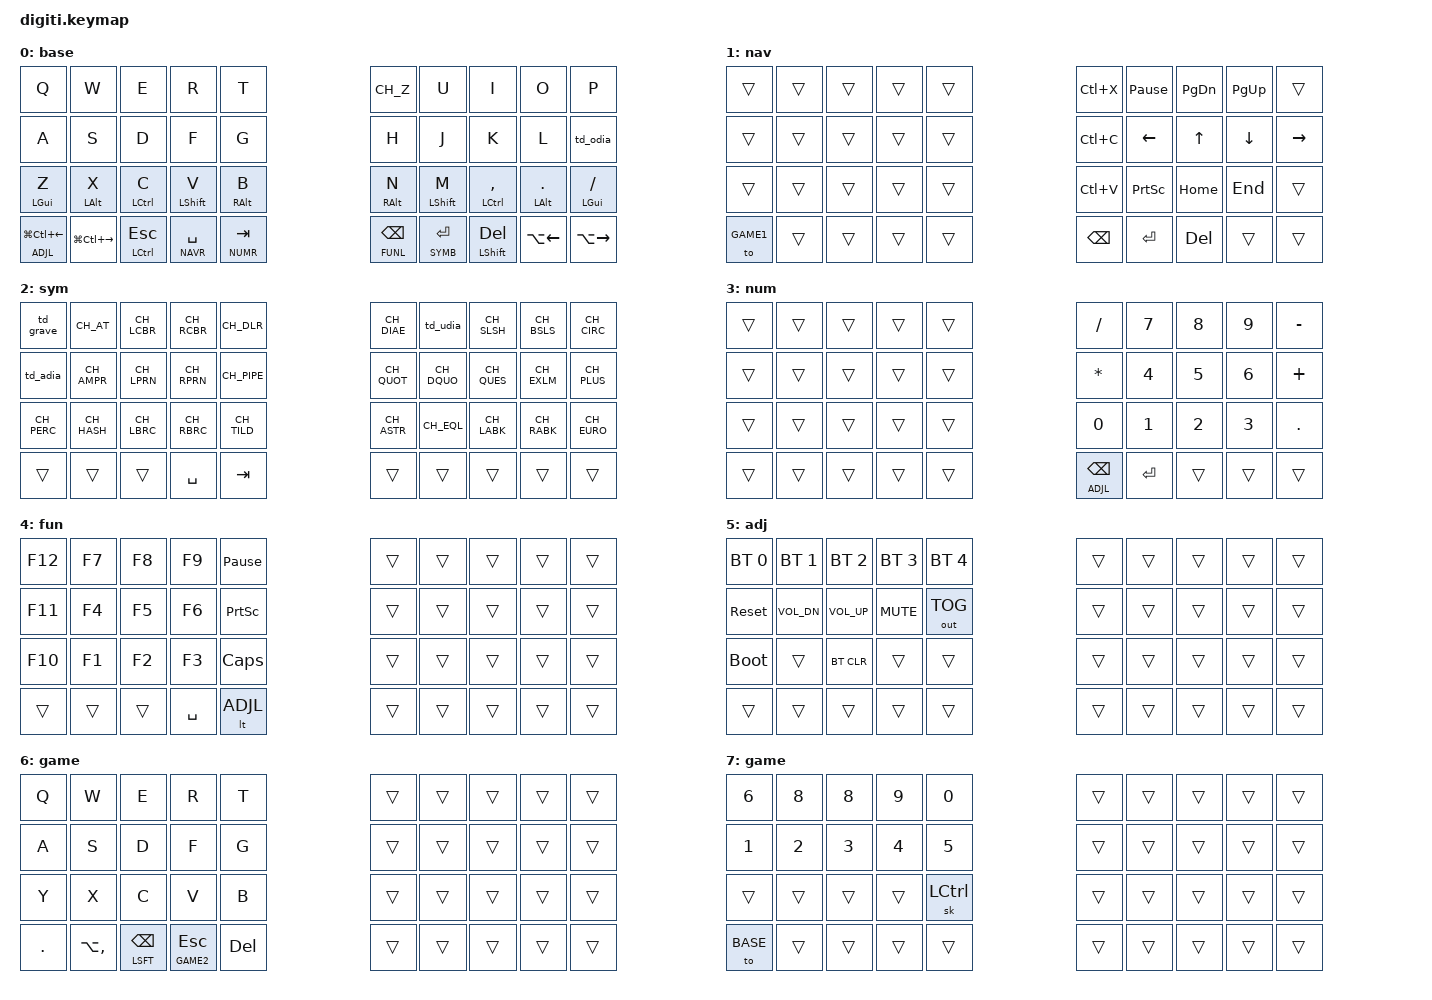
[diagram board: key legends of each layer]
/*
 * Copyright (c) 2021 The ZMK Contributors
 *
 * SPDX-License-Identifier: MIT
 */

 #include <behaviors.dtsi>
 #include <dt-bindings/zmk/keys.h>
 #include <dt-bindings/zmk/bt.h>
 #include <dt-bindings/zmk/ext_power.h>
 #include <dt-bindings/zmk/outputs.h>
 
 #include "swiss-keymap.h"
 
 #define BASE   0
 #define NAVR   1
 #define SYMB   2
 #define NUMR   3
 #define FUNL   4
 #define ADJL   5   
 #define GAME1  6    
 #define GAME2  7    
 
 / {
     macros {
        md_code_i: md_code_i {
            label = "MD Code Inline";
            compatible = "zmk,behavior-macro";
            #binding-cells = <0>;
            bindings
                = <&macro_tap_time 50>
                , <&macro_tap &kp CH_GRV>
                , <&macro_tap_time 10>
                , <&macro_tap &kp CH_GRV &kp LEFT>
                ;
        };
        md_code_b: md_code_b {
            label = "MD Code Block";
            compatible = "zmk,behavior-macro";
            #binding-cells = <0>;
            bindings
                = <&macro_tap_time 10>
                , <&macro_tap &kp CH_GRV &kp CH_GRV &kp CH_GRV &kp CH_GRV &kp CH_GRV &kp CH_GRV &kp LEFT &kp LEFT &kp LEFT &kp RET &kp RET &kp UP>
                ;
        };
        up_ch_adia: up_ch_adia {
            label = "Uppercase CH_ADIA";
            compatible = "zmk,behavior-macro";
            #binding-cells = <0>;
            bindings
                = <&macro_tap_time 10>
                , <&macro_tap &kp CLCK &kp CH_ADIA &kp CLCK>
                ;
        };
        up_ch_udia: up_ch_udia {
            label = "Uppercase CH_UDIA";
            compatible = "zmk,behavior-macro";
            #binding-cells = <0>;
            bindings
                = <&macro_tap_time 10>
                , <&macro_tap &kp CLCK &kp CH_UDIA &kp CLCK>
                ;
        };
        
        up_ch_odia: up_ch_odia {
            label = "Uppercase CH_ODIA";
            compatible = "zmk,behavior-macro";
            #binding-cells = <0>;
            bindings
                = <&macro_tap_time 10>
                , <&macro_tap &kp CLCK &kp CH_ODIA &kp CLCK>
                ;
        };
    };
     behaviors {
         hm: homerow_mods {
             compatible = "zmk,behavior-hold-tap";
             label = "HOMEROW_MODS";
             #binding-cells = <2>;
             tapping-term-ms = <180>;
             quick_tap_ms = <0>;
             flavor = "tap-preferred";
             bindings = <&kp>, <&kp>;
         };
         td_udia: tap_dance_udia {
            compatible = "zmk,behavior-tap-dance";
            label = "TAP_DANCE_UDIA";
            #binding-cells = <0>;
            tapping-term-ms = <200>;
            bindings = <&kp CH_UDIA>, <&up_ch_udia>;
        };
         td_adia: tap_dance_adia {
            compatible = "zmk,behavior-tap-dance";
            label = "TAP_DANCE_ADIA";
            #binding-cells = <0>;
            tapping-term-ms = <200>;
            bindings = <&kp CH_ADIA>, <&up_ch_adia>;
        };
         td_odia: tap_dance_odia {
            compatible = "zmk,behavior-tap-dance";
            label = "TAP_DANCE_ODIA";
            #binding-cells = <0>;
            tapping-term-ms = <200>;
            bindings = <&kp CH_ODIA>, <&up_ch_odia>;
        };
        td_grave: tap_dance_grave {
            compatible = "zmk,behavior-tap-dance";
            label = "TAP_DANCE_GRAVE";
            #binding-cells = <0>;
            tapping-term-ms = <300>;
            bindings = <&kp CH_GRV>, <&md_code_i>, <&md_code_b>;
        };
     };
 // /*
 //  *
 //  *               ,------------------------.                               ,------------------------.
 //  *               | 00 | 01 | 02 | 03 | 04 |                               | 05 | 06 | 07 | 08 | 09 |      
 //  *               |----+----+----+----+----|                               |----+----+----+----+----|
 //  *               | 10 | 11 | 12 | 13 | 14 |                               | 15 | 16 | 17 | 18 | 19 |
 //  *               |----+----+----+----+----|                               |----+----+----+----+----|
 //  *               | 20 | 21 | 22 | 23 | 24 |                               | 25 | 26 | 27 | 28 | 29 |
 //  *               `------------------------+----.                     ,----+----+-------------------'
 //  *                    | 30 | 31 | 32 | 33 | 34 |                     | 35 | 36 | 37 | 38 | 39 |
 //  *                    `------------------------'                     `------------------------'
 //  */
     combos {
         compatible = "zmk,combos";
         combo_ctrl_t {
             timeout-ms = <50>;
             key-positions = <4 14>;
             bindings = <&kp LC(T)>;
         };
         combo_ctrl_z {
             timeout-ms = <50>;
             key-positions = <5 15>;
             bindings = <&kp LC(CH_Z)>;
         };
         combo_delete_left {
             timeout-ms = <50>;
             key-positions = <12 22>;
             bindings = <&kp DEL>;
         };
         combo_enter_left {
             timeout-ms = <50>;
             key-positions = <13 23>;
             bindings = <&kp ENTER>;
         };
         combo_caps_word {
             timeout-ms = <50>;
             key-positions = <23 26>;
             bindings = <&caps_word>;
         };
     };
     keymap {
         compatible = "zmk,keymap";
         base {
             label = "base";
 //  *                               ,----------------------------------.                                                                         ,----------------------------------.
 //  *                               |   Q  |   W  |   E  |   R  |   T  |                                                                         |   Y  |   U  |   I  |   O  |   P  |      
 //  *                               |      |      |      |      |      |                                                                         |      |      |      |      |      |      
 //  *                               |------+------+------+------+------|                                                                         |------+------+------+------+------|
 //  *                               |   A  |   S  |   D  |   F  |   G  |                                                                         |   H  |   J  |   K  |   L  |  ; : |
 //  *                               |      |      |      |      |      |                                                                         |      |      |      |      |      |
 //  *                               |------+------+------+------+------|                                                                         |------+------+------+------+------|
 //  *                               |   Z  |   X  |   C  |   V  |   B  |                                                                         |   N  |   M  |  , < |  . > |  / ? |
 //  *                               |  GUI | LALT | LCTL | LSFT | RALT |                                                                         | RALT | LSFT | LCTL | LALT |  GUI |
 //  *                               `---------------------------+------+------.                                                           ,------+------+---------------------------'
 //  *                                      |  <<= |  =>> |  ESC | Space| TAB  |                                                           | Bksp | Enter| Del  |  <=  |  =>  |
 //  *                                      |      |      |  CTL | NAVR | NUMR |                                                           | FUNL | SYML | LSFT |      |      |
 //  *                                      `----------------------------------'                                                           `----------------------------------'
             bindings = <
                     &kp Q         &kp W             &kp E             &kp R          &kp T                                                 &kp CH_Z       &kp U           &kp I           &kp O          &kp P 
                     &kp A         &kp S             &kp D             &kp F          &kp G                                                 &kp H          &kp J           &kp K           &kp L          &td_odia         
                     &hm LGUI Z    &hm LALT X        &hm LCTRL C       &hm LSHFT V    &hm RALT B                                            &hm RALT N     &hm LSHFT M     &hm LCTRL COMMA &hm LALT DOT   &hm LGUI FSLH
                              &lt ADJL LG(LC(LEFT))  &kp LG(LC(RIGHT)) &mt LCTRL ESC  &lt NAVR SPACE &lt NUMR TAB             &lt FUNL BSPC &lt SYMB RET   &mt LSHIFT DEL  &kp LA(LEFT)    &kp LA(RIGHT)
            >;
         };
         navr {
             label = "nav";
 //  *                               ,----------------------------------.                                                                       ,----------------------------------.
 //  *                               |      |      |      |      |      |                                                                       |  Cut | Break| PgUp | PgDwn|      |      
 //  *                               |      |      |      |      |      |                                                                       |      |      |      |      |      |      
 //  *                               |------+------+------+------+------|                                                                       |------+------+------+------+------|
 //  *                               |      |      |      |      |      |                                                                       | Copy |   ←  |   ↑  |   ↓  |   →  |
 //  *                               |      |      |      |      |      |                                                                       |      |      |      |      |      |
 //  *                               |------+------+------+------+------|                                                                       |------+------+------+------+------|
 //  *                               |      |      |      |      |      |                                                                       | Paste|PrScrn| Home |  End |      |
 //  *                               |      |      |      |      |      |                                                                       |      |      |      |      |      |
 //  *                               `---------------------------+------+------.                                                         ,------+------+---------------------------'
 //  *                                      |      |      |      |      |      |                                                         | Bksp | Enter|  Del |      |      |
 //  *                                      |      |      |      |      |      |                                                         |      |      |      |      |      |
 //  *                                      `----------------------------------'                                                         `----------------------------------'
             bindings = <
                     &trans         &trans         &trans         &trans        &trans                                            &kp LC(X)      &kp PAUSE_BREAK &kp PG_DN      &kp PG_UP     &trans
                     &trans         &trans         &trans         &trans        &trans                                            &kp LC(C)      &kp LEFT        &kp UP         &kp DOWN      &kp RIGHT   
                     &trans         &trans         &trans         &trans        &trans                                            &kp LC(V)      &kp PSCRN       &kp HOME       &kp END       &trans        
                                    &to GAME1      &trans         &trans        &trans        &trans                  &kp BSPC    &kp RET        &kp DEL         &trans         &trans 
             >;
         };
         symb {
             label = "sym";
 //  *                               ,----------------------------------.                                                                       ,----------------------------------.
//  *                                |   `  |   @  |  {   |   }  |  $   |                                                                       |   ¨  |   ü  |  /   |  \   |  ^   |      
 //  *                               |      |      |      |      |      |                                                                       |      |      |      |      |      |      
 //  *                               |------+------+------+------+------|                                                                       |------+------+------+------+------|
 //  *                               |   ä  |   &  |  (   |   )  |  |   |                                                                       |   '  |   "  |  ?   |  !   |  +   |
 //  *                               |      |      |      |      |      |                                                                       |      |      |      |      |      |
 //  *                               |------+------+------+------+------|                                                                       |------+------+------+------+------|
 //  *                               |   %  |   #  |  [   |   ]  |  ~   |                                                                       |   *  |   =  |  <   |  >   |  €   |
 //  *                               |      |      |      |      |      |                                                                       |      |      |      |      |      |
 //  *                               `---------------------------+------+------.                                                         ,------+------+---------------------------'
 //  *                                      |      |      |      |      |      |                                                         |      |      |      |      |      |
 //  *                                      |      |      |      |      |      |                                                         |      |      |      |      |      |
 //  *                                      `----------------------------------'                                                         `----------------------------------'
             bindings = <
                     &td_grave      &kp CH_AT      &kp CH_LCBR     &kp CH_RCBR    &kp CH_DLR                                             &kp CH_DIAE    &td_udia       &kp CH_SLSH    &kp CH_BSLS    &kp CH_CIRC
                     &td_adia       &kp CH_AMPR    &kp CH_LPRN     &kp CH_RPRN    &kp CH_PIPE                                            &kp CH_QUOT    &kp CH_DQUO    &kp CH_QUES    &kp CH_EXLM    &kp CH_PLUS
                     &kp CH_PERC    &kp CH_HASH    &kp CH_LBRC     &kp CH_RBRC    &kp CH_TILD                                            &kp CH_ASTR    &kp CH_EQL     &kp CH_LABK    &kp CH_RABK    &kp CH_EURO    
                                    &trans         &trans         &trans          &kp SPACE      &kp TAB                  &trans         &trans         &trans         &trans         &trans 
             >;
         };
         numr {
             label = "num";
 //  *                               ,----------------------------------.                                                                       ,----------------------------------.
 //  *                               |      |      |      |      |      |                                                                       |  /   |   7  |   8  |   9  |  -   |      
 //  *                               |      |      |      |      |      |                                                                       |      |      |      |      |      |      
 //  *                               |------+------+------+------+------|                                                                       |------+------+------+------+------|
 //  *                               |      |      |      |      |      |                                                                       |  *   |   4  |   5  |   6  |  +   |
 //  *                               |      |      |      |      |      |                                                                       |      |      |      |      |      |
 //  *                               |------+------+------+------+------|                                                                       |------+------+------+------+------|
 //  *                               |      |      |      |      |      |                                                                       |  0   |   1  |   2  |   3  |  .   |
 //  *                               |      |      |      |      |      |                                                                       |      |      |      |      |      |
 //  *                               `---------------------------+------+------.                                                         ,------+------+---------------------------'
 //  *                                      |      |      |      |      |      |                                                         | Bksp | Enter|      |      |      |
 //  *                                      |      |      |      |      |      |                                                         | ADJL |      |      |      |      |
 //  *                                      `----------------------------------'                                                         `----------------------------------'
             bindings = <
                     &trans         &trans         &trans         &trans        &trans                                               &kp SLASH      &kp N7         &kp N8         &kp N9         &kp MINUS
                     &trans         &trans         &trans         &trans        &trans                                               &kp ASTRK      &kp N4         &kp N5         &kp N6         &kp PLUS 
                     &trans         &trans         &trans         &trans        &trans                                               &kp N0         &kp N1         &kp N2         &kp N3         &kp DOT    
                                    &trans         &trans         &trans        &trans        &trans                  &lt ADJL BSPC  &kp RET        &trans         &trans         &trans 
             >;
         };
         funl {
             label = "fun";
 //  *                               ,----------------------------------.                                                                       ,----------------------------------.
 //  *                               | F12  |  F7  |  F8  |  F9  | Break|                                                                       |      |      |      |      |      |      
 //  *                               |      |      |      |      |      |                                                                       |      |      |      |      |      |      
 //  *                               |------+------+------+------+------|                                                                       |------+------+------+------+------|
 //  *                               | F11  |  F4  |  F5  |  F6  | PrScr|                                                                       |      |      |      |      |      |
 //  *                               |      |      |      |      |      |                                                                       |      |      |      |      |      |
 //  *                               |------+------+------+------+------|                                                                       |------+------+------+------+------|
 //  *                               | F10  |  F1  |  F2  |  F3  | CapL |                                                                       |      |      |      |      |      |
 //  *                               |      |      |      |      |      |                                                                       |      |      |      |      |      |
 //  *                               `---------------------------+------+------.                                                         ,------+------+---------------------------'
 //  *                                      |      |      |      | Space|  ADJ |                                                         |      |      |      |      |      |
 //  *                                      |      |      |      |      |      |                                                         |      |      |      |      |      |
 //  *                                      `----------------------------------'                                                         `----------------------------------'
             bindings = <
                     &kp F12        &kp F7         &kp F8          &kp F9         &kp PAUSE_BREAK                                 &trans        &trans         &trans        &trans        &trans 
                     &kp F11        &kp F4         &kp F5          &kp F6         &kp PSCRN                                       &trans        &trans         &trans        &trans        &trans
                     &kp F10        &kp F1         &kp F2          &kp F3         &kp CLCK                                        &trans        &trans         &trans        &trans        &trans     
                                    &trans         &trans         &trans          &kp SPACE      &lt ADJL             &trans      &trans        &trans         &trans        &trans     
             >;
         };
         adjl {
             label = "adj";
 //  *                               ,----------------------------------.                                                                       ,----------------------------------.
 //  *                               |      |      |      |      |      |                                                                       |      |      |      |      |      |      
 //  *                               |      |      |      |      |      |                                                                       |      |      |      |      |      |      
 //  *                               |------+------+------+------+------|                                                                       |------+------+------+------+------|
 //  *                               |      |      |      |      |      |                                                                       |      |      |      |      |      |
 //  *                               |      |      |      |      |      |                                                                       |      |      |      |      |      |
 //  *                               |------+------+------+------+------|                                                                       |------+------+------+------+------|
 //  *                               |      |      |      |      |      |                                                                       |      |      |      |      |      |
 //  *               q                |      |      |      |      |      |                                                                       |      |      |      |      |      |
 //  *                               `---------------------------+------+------.                                                         ,------+------+---------------------------'
 //  *                                      |      |      |      |      |      |                                                         |      |      |      |      |      |
 //  *                                      |      |      |      |      |      |                                                         |      |      |      |      |      |
 //  *                                      `----------------------------------'                                                         `----------------------------------'
             bindings = <
                     &bt BT_SEL 0   &bt BT_SEL 1   &bt BT_SEL 2   &bt BT_SEL 3  &bt BT_SEL 4                                         &trans        &trans         &trans        &trans        &trans 
                     &sys_reset         &kp C_VOL_DN   &kp C_VOL_UP   &kp K_MUTE    &out OUT_TOG                                         &trans        &trans         &trans        &trans        &trans
                     &bootloader    &trans         &bt BT_CLR     &trans        &trans                                               &trans        &trans         &trans        &trans        &trans     
                                    &trans         &trans         &trans        &trans        &trans                   &trans        &trans        &trans         &trans        &trans     
             >;
         };
         game1 {
             label = "game";
 //  *                               ,----------------------------------.                                                                       ,----------------------------------.
 //  *                               |   Q  |   W  |   E  |   R  |   T  |                                                                       |      |      |      |      |      |      
 //  *                               |      |      |      |      |      |                                                                       |      |      |      |      |      |      
 //  *                               |------+------+------+------+------|                                                                       |------+------+------+------+------|
 //  *                               |   A  |   S  |   D  |   F  |   G  |                                                                       |      |      |      |      |      |
 //  *                               |      |      |      |      |      |                                                                       |      |      |      |      |      |
 //  *                               |------+------+------+------+------|                                                                       |------+------+------+------+------|
 //  *                               |   Y  |   X  |   C  |   V  |  B   |                                                                       |      |      |      |      |      |
 //  *                               |      |      |      |      |      |                                                                       |      |      |      |      |      |
 //  *                               `---------------------------+------+------.                                                         ,------+------+---------------------------'
 //  *                                      |   .  | Alt+,| BSPC |  Esc |  Del |                                                         |      |      |      |      |      |
 //  *                                      |      |      | Shft | GAME2|      |                                                         |      |      |      |      |      |
 //  *                                      `----------------------------------'                                                         `----------------------------------'
            bindings = <
                     &kp Q          &kp W          &kp E          &kp R         &kp T                                               &trans        &trans         &trans        &trans        &trans 
                     &kp A          &kp S          &kp D          &kp F         &kp G                                               &trans        &trans         &trans        &trans        &trans
                     &kp Y          &kp X          &kp C          &kp V         &kp B                                               &trans        &trans         &trans        &trans        &trans     
                                    &kp DOT        &kp LA(COMMA)  &mt LSFT BSPC      &lt GAME2 ESC     &kp DEL             &trans        &trans        &trans         &trans        &trans     
             >;
         };
         game2 {
             label = "game";
 //  *                               ,----------------------------------.                                                                       ,----------------------------------.
 //  *                               |   6  |   7  |   8  |   9  |   0  |                                                                       |      |      |      |      |      |      
 //  *                               |      |      |      |      |      |                                                                       |      |      |      |      |      |      
 //  *                               |------+------+------+------+------|                                                                       |------+------+------+------+------|
 //  *                               |   1  |   2  |   3  |   4  |   5  |                                                                       |      |      |      |      |      |
 //  *                               |      |      |      |      |      |                                                                       |      |      |      |      |      |
 //  *                               |------+------+------+------+------|                                                                       |------+------+------+------+------|
 //  *                               |      |      |      |      | LCTR |                                                                       |      |      |      |      |      |
 //  *                               |      |      |      |      |      |                                                                       |      |      |      |      |      |
 //  *                               `---------------------------+------+------.                                                         ,------+------+---------------------------'
 //  *                                      |      |      |      |      |      |                                                         |      |      |      |      |      |
 //  *                                      |      |      |      |      |      |                                                         |      |      |      |      |      |
 //  *                                      `----------------------------------'                                                         `----------------------------------'
            bindings = <
                     &kp N6         &kp N8         &kp N8         &kp N9        &kp N0                                               &trans        &trans         &trans        &trans        &trans 
                     &kp N1         &kp N2         &kp N3         &kp N4        &kp N5                                               &trans        &trans         &trans        &trans        &trans
                     &trans         &trans         &trans         &trans        &sk LCTRL                                              &trans        &trans         &trans        &trans        &trans     
                                    &to BASE       &trans         &trans        &trans        &trans                   &trans        &trans        &trans         &trans        &trans     
             >;
         };
    };
};
/*
         layer {
             label = "template";
 //  *                               ,----------------------------------.                                                                       ,----------------------------------.
 //  *                               |      |      |      |      |      |                                                                       |      |      |      |      |      |      
 //  *                               |      |      |      |      |      |                                                                       |      |      |      |      |      |      
 //  *                               |------+------+------+------+------|                                                                       |------+------+------+------+------|
 //  *                               |      |      |      |      |      |                                                                       |      |      |      |      |      |
 //  *                               |      |      |      |      |      |                                                                       |      |      |      |      |      |
 //  *                               |------+------+------+------+------|                                                                       |------+------+------+------+------|
 //  *                               |      |      |      |      |      |                                                                       |      |      |      |      |      |
 //  *                               |      |      |      |      |      |                                                                       |      |      |      |      |      |
 //  *                               `---------------------------+------+------.                                                         ,------+------+---------------------------'
 //  *                                      |      |      |      |      |      |                                                         |      |      |      |      |      |
 //  *                                      |      |      |      |      |      |                                                         |      |      |      |      |      |
 //  *                                      `----------------------------------'                                                         `----------------------------------'
            bindings = <
                     &trans         &trans         &trans         &trans        &trans                                               &trans        &trans         &trans        &trans        &trans 
                     &trans         &trans         &trans         &trans        &trans                                               &trans        &trans         &trans        &trans        &trans
                     &trans         &trans         &trans         &trans        &trans                                               &trans        &trans         &trans        &trans        &trans     
                                    &trans         &trans         &trans        &trans        &trans                   &trans        &trans        &trans         &trans        &trans     
             >;
         };
*/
